AUTOSAR XML (schema 4-2-2)
package /ComponentTypes
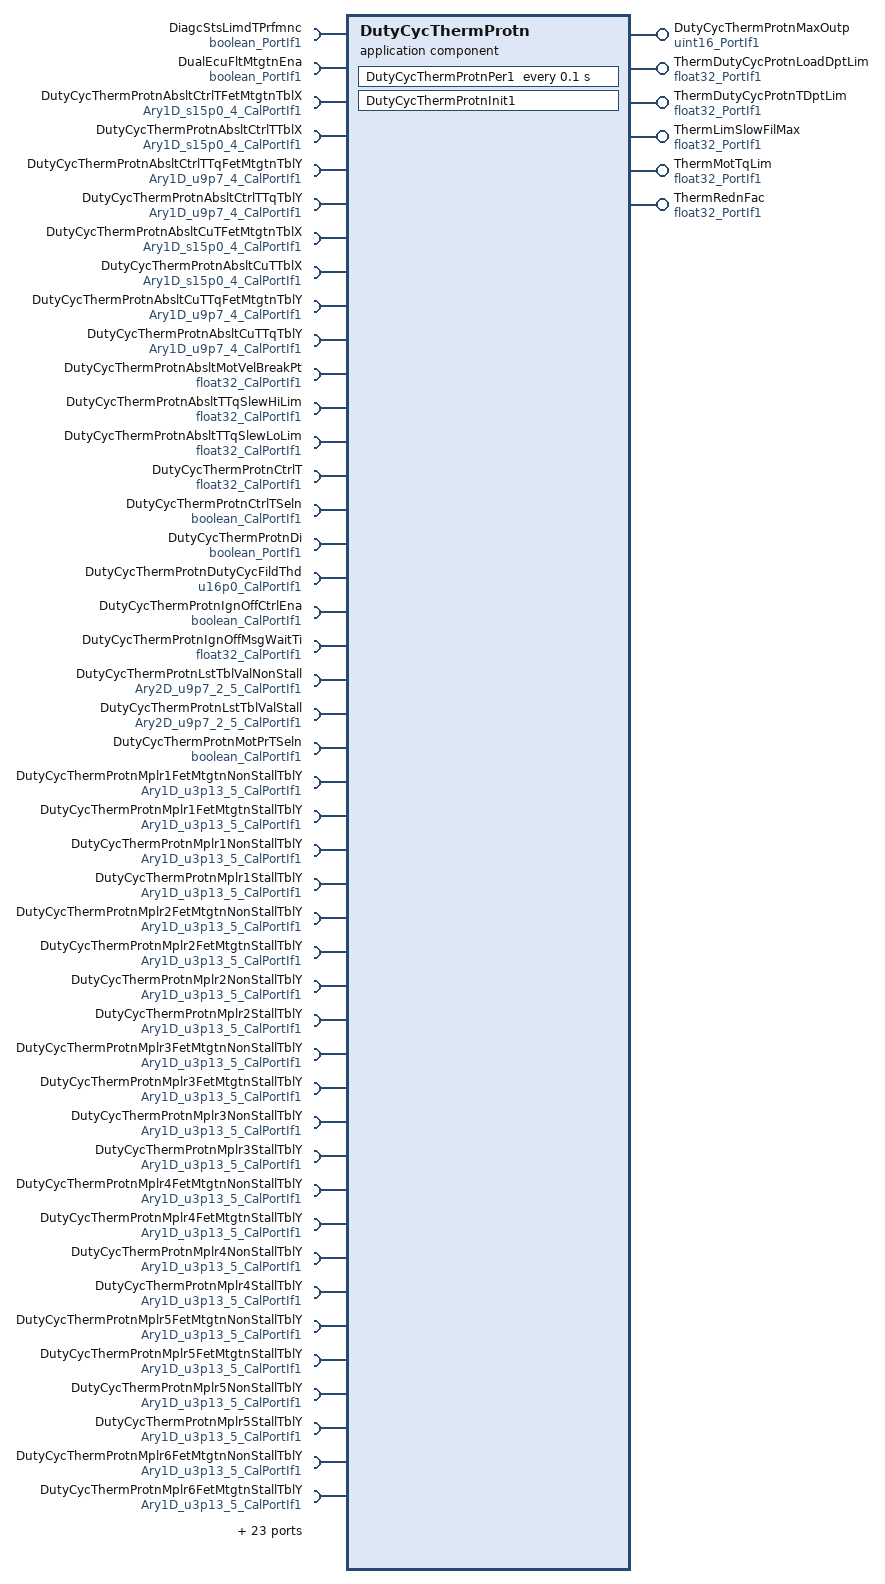
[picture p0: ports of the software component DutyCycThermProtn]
  application sw component type DutyCycThermProtn
    6 x provide port:
      DutyCycThermProtnMaxOutp: nonqueued-sender-com-spec{data-element=Val, init-value=0}, provided-interface=uint16_PortIf1
      ThermDutyCycProtnLoadDptLim: nonqueued-sender-com-spec{data-element=Val, init-value=8.8}, provided-interface=float32_PortIf1
      ThermDutyCycProtnTDptLim: nonqueued-sender-com-spec{data-element=Val, init-value=8.8}, provided-interface=float32_PortIf1
      ThermLimSlowFilMax: nonqueued-sender-com-spec{data-element=Val, init-value=0}, provided-interface=float32_PortIf1
      ThermMotTqLim: nonqueued-sender-com-spec{data-element=Val, init-value=0}, provided-interface=float32_PortIf1
      ThermRednFac: nonqueued-sender-com-spec{data-element=Val, init-value=0}, provided-interface=float32_PortIf1
    67 x require port:
      DiagcStsLimdTPrfmnc: nonqueued-receiver-com-spec{data-element=Logl, filter=data-filter-type=ALWAYS, init-value=0}, required-interface=boolean_PortIf1
      DualEcuFltMtgtnEna: nonqueued-receiver-com-spec{data-element=Logl, filter=data-filter-type=ALWAYS, init-value=0}, required-interface=boolean_PortIf1
      DutyCycThermProtnAbsltCtrlTFetMtgtnTblX: parameter-require-com-spec{init-value=[122, 123, 125, 127], parameter=Ary1D}, required-interface=Ary1D_s15p0_4_CalPortIf1
      DutyCycThermProtnAbsltCtrlTTblX: parameter-require-com-spec{init-value=[122, 123, 125, 127], parameter=Ary1D}, required-interface=Ary1D_s15p0_4_CalPortIf1
      DutyCycThermProtnAbsltCtrlTTqFetMtgtnTblY: parameter-require-com-spec{init-value=[346, 287, 234, 0], parameter=Ary1D}, required-interface=Ary1D_u9p7_4_CalPortIf1
      DutyCycThermProtnAbsltCtrlTTqTblY: parameter-require-com-spec{init-value=[346, 287, 234, 0], parameter=Ary1D}, required-interface=Ary1D_u9p7_4_CalPortIf1
      DutyCycThermProtnAbsltCuTFetMtgtnTblX: parameter-require-com-spec{init-value=[122, 123, 125, 127], parameter=Ary1D}, required-interface=Ary1D_s15p0_4_CalPortIf1
      DutyCycThermProtnAbsltCuTTblX: parameter-require-com-spec{init-value=[122, 123, 125, 127], parameter=Ary1D}, required-interface=Ary1D_s15p0_4_CalPortIf1
      DutyCycThermProtnAbsltCuTTqFetMtgtnTblY: parameter-require-com-spec{init-value=[346, 287, 234, 0], parameter=Ary1D}, required-interface=Ary1D_u9p7_4_CalPortIf1
      DutyCycThermProtnAbsltCuTTqTblY: parameter-require-com-spec{init-value=[346, 287, 234, 0], parameter=Ary1D}, required-interface=Ary1D_u9p7_4_CalPortIf1
      DutyCycThermProtnAbsltMotVelBreakPt: parameter-require-com-spec{init-value=1.375, parameter=Val}, required-interface=float32_CalPortIf1
      DutyCycThermProtnAbsltTTqSlewHiLim: parameter-require-com-spec{init-value=0.3, parameter=Val}, required-interface=float32_CalPortIf1
      DutyCycThermProtnAbsltTTqSlewLoLim: parameter-require-com-spec{init-value=0.3, parameter=Val}, required-interface=float32_CalPortIf1
      DutyCycThermProtnCtrlT: parameter-require-com-spec{init-value=70, parameter=Val}, required-interface=float32_CalPortIf1
      DutyCycThermProtnCtrlTSeln: parameter-require-com-spec{init-value=1, parameter=Logl}, required-interface=boolean_CalPortIf1
      DutyCycThermProtnDi: nonqueued-receiver-com-spec{data-element=Logl, filter=data-filter-type=ALWAYS, init-value=0}, required-interface=boolean_PortIf1
      DutyCycThermProtnDutyCycFildThd: parameter-require-com-spec{init-value=92, parameter=Val}, required-interface=u16p0_CalPortIf1
      DutyCycThermProtnIgnOffCtrlEna: parameter-require-com-spec{init-value=0, parameter=Logl}, required-interface=boolean_CalPortIf1
      DutyCycThermProtnIgnOffMsgWaitTi: parameter-require-com-spec{init-value=0.5, parameter=Val}, required-interface=float32_CalPortIf1
      DutyCycThermProtnLstTblValNonStall: parameter-require-com-spec{init-value=[[128, 128, 128, 44, 44], [128, 128, 128, 44, 44]], parameter=Ary2D}, required-interface=Ary2D_u9p7_2_5_CalPortIf1
      DutyCycThermProtnLstTblValStall: parameter-require-com-spec{init-value=[[124, 124, 124, 40, 40], [124, 124, 124, 40, 40]], parameter=Ary2D}, required-interface=Ary2D_u9p7_2_5_CalPortIf1
      DutyCycThermProtnMotPrTSeln: parameter-require-com-spec{init-value=1, parameter=Logl}, required-interface=boolean_CalPortIf1
      DutyCycThermProtnMplr1FetMtgtnNonStallTblY: parameter-require-com-spec{init-value=[127, 127, 127, 1630, 1630], parameter=Ary1D}, required-interface=Ary1D_u3p13_5_CalPortIf1
      DutyCycThermProtnMplr1FetMtgtnStallTblY: parameter-require-com-spec{init-value=[133, 133, 133, 180, 180], parameter=Ary1D}, required-interface=Ary1D_u3p13_5_CalPortIf1
      DutyCycThermProtnMplr1NonStallTblY: parameter-require-com-spec{init-value=[127, 127, 127, 1630, 1630], parameter=Ary1D}, required-interface=Ary1D_u3p13_5_CalPortIf1
      DutyCycThermProtnMplr1StallTblY: parameter-require-com-spec{init-value=[133, 133, 133, 180, 180], parameter=Ary1D}, required-interface=Ary1D_u3p13_5_CalPortIf1
      DutyCycThermProtnMplr2FetMtgtnNonStallTblY: parameter-require-com-spec{init-value=[159, 159, 159, 281, 281], parameter=Ary1D}, required-interface=Ary1D_u3p13_5_CalPortIf1
      DutyCycThermProtnMplr2FetMtgtnStallTblY: parameter-require-com-spec{init-value=[167, 167, 167, 310, 310], parameter=Ary1D}, required-interface=Ary1D_u3p13_5_CalPortIf1
      DutyCycThermProtnMplr2NonStallTblY: parameter-require-com-spec{init-value=[159, 159, 159, 281, 281], parameter=Ary1D}, required-interface=Ary1D_u3p13_5_CalPortIf1
      DutyCycThermProtnMplr2StallTblY: parameter-require-com-spec{init-value=[167, 167, 167, 310, 310], parameter=Ary1D}, required-interface=Ary1D_u3p13_5_CalPortIf1
      DutyCycThermProtnMplr3FetMtgtnNonStallTblY: parameter-require-com-spec{init-value=[199, 199, 199, 1282, 1282], parameter=Ary1D}, required-interface=Ary1D_u3p13_5_CalPortIf1
      DutyCycThermProtnMplr3FetMtgtnStallTblY: parameter-require-com-spec{init-value=[210, 210, 210, 1707, 1707], parameter=Ary1D}, required-interface=Ary1D_u3p13_5_CalPortIf1
      DutyCycThermProtnMplr3NonStallTblY: parameter-require-com-spec{init-value=[199, 199, 199, 1282, 1282], parameter=Ary1D}, required-interface=Ary1D_u3p13_5_CalPortIf1
      DutyCycThermProtnMplr3StallTblY: parameter-require-com-spec{init-value=[210, 210, 210, 1707, 1707], parameter=Ary1D}, required-interface=Ary1D_u3p13_5_CalPortIf1
      DutyCycThermProtnMplr4FetMtgtnNonStallTblY: parameter-require-com-spec{init-value=5 x 1, parameter=Ary1D}, required-interface=Ary1D_u3p13_5_CalPortIf1
      DutyCycThermProtnMplr4FetMtgtnStallTblY: parameter-require-com-spec{init-value=5 x 1, parameter=Ary1D}, required-interface=Ary1D_u3p13_5_CalPortIf1
      DutyCycThermProtnMplr4NonStallTblY: parameter-require-com-spec{init-value=5 x 1, parameter=Ary1D}, required-interface=Ary1D_u3p13_5_CalPortIf1
      DutyCycThermProtnMplr4StallTblY: parameter-require-com-spec{init-value=5 x 1, parameter=Ary1D}, required-interface=Ary1D_u3p13_5_CalPortIf1
      DutyCycThermProtnMplr5FetMtgtnNonStallTblY: parameter-require-com-spec{init-value=[998, 998, 998, 9535, 9535], parameter=Ary1D}, required-interface=Ary1D_u3p13_5_CalPortIf1
      DutyCycThermProtnMplr5FetMtgtnStallTblY: parameter-require-com-spec{init-value=[998, 998, 998, 9535, 9535], parameter=Ary1D}, required-interface=Ary1D_u3p13_5_CalPortIf1
      DutyCycThermProtnMplr5NonStallTblY: parameter-require-com-spec{init-value=[998, 998, 998, 9535, 9535], parameter=Ary1D}, required-interface=Ary1D_u3p13_5_CalPortIf1
      DutyCycThermProtnMplr5StallTblY: parameter-require-com-spec{init-value=[998, 998, 998, 9535, 9535], parameter=Ary1D}, required-interface=Ary1D_u3p13_5_CalPortIf1
      DutyCycThermProtnMplr6FetMtgtnNonStallTblY: parameter-require-com-spec{init-value=5 x 1, parameter=Ary1D}, required-interface=Ary1D_u3p13_5_CalPortIf1
      DutyCycThermProtnMplr6FetMtgtnStallTblY: parameter-require-com-spec{init-value=5 x 1, parameter=Ary1D}, required-interface=Ary1D_u3p13_5_CalPortIf1
      DutyCycThermProtnMplr6NonStallTblY: parameter-require-com-spec{init-value=5 x 1, parameter=Ary1D}, required-interface=Ary1D_u3p13_5_CalPortIf1
      DutyCycThermProtnMplr6StallTblY: parameter-require-com-spec{init-value=5 x 1, parameter=Ary1D}, required-interface=Ary1D_u3p13_5_CalPortIf1
      DutyCycThermProtnMplrFetMtgtnTblX: parameter-require-com-spec{init-value=[-40, 0, 83, 84, 85], parameter=Ary1D}, required-interface=Ary1D_s15p0_5_CalPortIf1
      DutyCycThermProtnMplrTblX: parameter-require-com-spec{init-value=[-40, 0, 83, 84, 85], parameter=Ary1D}, required-interface=Ary1D_s15p0_5_CalPortIf1
      DutyCycThermProtnMplrTSeln: parameter-require-com-spec{init-value=1, parameter=Logl}, required-interface=boolean_CalPortIf1
      DutyCycThermProtnSlowFilTSeln: parameter-require-com-spec{init-value=0, parameter=Logl}, required-interface=boolean_CalPortIf1
      DutyCycThermProtnThermLimScaFac: parameter-require-com-spec{init-value=0.5, parameter=Val}, required-interface=float32_CalPortIf1
      DutyCycThermProtnThermLoadLimTblX: parameter-require-com-spec{init-value=[[0, 76, 80, 84, 88, 92, 96, 100], [0, 76, 80, 84, 88, 92, 96, 100]], parameter=Ary2D}, required-interface=Ary2D_u16p0_2_8_CalPortIf1
      DutyCycThermProtnThermLoadLimTblY: parameter-require-com-spec{init-value=[[346, 346, 346, 346, 287, 234, 181, 128], [346, 346, 346, 346, 287, 234, 181, 128]], parameter=Ary2D}, required-interface=Ary2D_u9p7_2_8_CalPortIf1
      DutyCycThermProtnTqCmdSlewDwn: parameter-require-com-spec{init-value=0.3, parameter=Val}, required-interface=float32_CalPortIf1
      DutyCycThermProtnTqCmdSlewUp: parameter-require-com-spec{init-value=0.3, parameter=Val}, required-interface=float32_CalPortIf1
      EcuTFild: nonqueued-receiver-com-spec{data-element=Val, filter=data-filter-type=ALWAYS, init-value=25}, required-interface=float32_PortIf1
      FilStVal: required-com-specs=[EraseBlock, GetErrorStatus, InvalidateNvBlock, ReadBlock, SetRamBlockStatus, WriteBlock], required-interface=NvMService_AC3_SRBS
      IgnTiOff: nonqueued-receiver-com-spec{data-element=Val, filter=data-filter-type=ALWAYS, init-value=0}, required-interface=uint32_PortIf1
      MotAndThermProtnLoaMod: nonqueued-receiver-com-spec{data-element=Val, filter=data-filter-type=ALWAYS, init-value=0}, required-interface=uint8_PortIf1
      MotCurrPeakEstimd: nonqueued-receiver-com-spec{data-element=Val, filter=data-filter-type=ALWAYS, init-value=0}, required-interface=float32_PortIf1
      MotCurrPeakEstimdFild: nonqueued-receiver-com-spec{data-element=Val, filter=data-filter-type=ALWAYS, init-value=0}, required-interface=float32_PortIf1
      MotFetT: nonqueued-receiver-com-spec{data-element=Val, filter=data-filter-type=ALWAYS, init-value=0}, required-interface=float32_PortIf1
      MotMagT: nonqueued-receiver-com-spec{data-element=Val, filter=data-filter-type=ALWAYS, init-value=0}, required-interface=float32_PortIf1
      MotVelCrf: nonqueued-receiver-com-spec{data-element=Val, filter=data-filter-type=ALWAYS, init-value=0}, required-interface=float32_PortIf1
      MotWidgT: nonqueued-receiver-com-spec{data-element=Val, filter=data-filter-type=ALWAYS, init-value=0}, required-interface=float32_PortIf1
      SetNtcSts: client-com-spec=Oper, required-interface=SetNtcSts_PortIf1
      VehTiVld: nonqueued-receiver-com-spec{data-element=Logl, filter=data-filter-type=ALWAYS, init-value=0}, required-interface=boolean_PortIf1
    behavior DutyCycThermProtn_InternalBehavior
      ar-typed-per-instance-memorys:
        32 x data, all with sw-calibration-access=READ-ONLY:
          AbsltTLimSlewStVari: type=float32
          dDutyCycThermProtnAbsltCtrlrTTqLim: type=float32
          dDutyCycThermProtnAbsltCuTTqLim: type=float32
          dDutyCycThermProtnAbsltTTqLim: type=float32
          dDutyCycThermProtnLstTblVal: type=u9p7
          dDutyCycThermProtnLstTblValSlew: type=u9p7
          dDutyCycThermProtnMplr1: type=u3p13
          dDutyCycThermProtnMplr12T: type=float32
          dDutyCycThermProtnMplr2: type=u3p13
          dDutyCycThermProtnMplr3: type=u3p13
          dDutyCycThermProtnMplr36T: type=float32
          dDutyCycThermProtnMplr{4..6}: type=u3p13
          dDutyCycThermProtnThermLoadLim: type=float32
          dDutyCycThermProtnThermLoadLimTblYVal: type=float32
          FetLoaMtgtnEnaPrev: type=boolean
          FetMtgtnEnaCalIdx: type=uint8
          Fil1ValStVari: type=FilLpRec1
          Fil2ValStVari: type=FilLpRec1
          Fil{3..6}ValPwrUp: type=uint8
          Fild{3..6}Val: type=FilLpRec1
          FilStVal: type=DutyCycThermProtnFilStValRec1
          LstTblValRateLimrStVari: type=float32
          ReInitCntrFlg: type=boolean
          ReInitCntrVal: type=float32
      init event DutyCycThermProtn_InitEvent: start-on-event=DutyCycThermProtnInit1
      timing event TMT_DutyCycThermProtnPer1: start-on-event=DutyCycThermProtnPer1, period=0.1
      explicit-inter-runnable-variables:
        data FilStVariReInitFlg: type=boolean, init-value=0
      runnable DutyCycThermProtnInit1
        data-receive-point-by-arguments:
          4 x access:
            REC_DutyCycThermProtnDi_Logl: accessed-variable=DutyCycThermProtnDi.Logl
            REC_IgnTiOff_Val: accessed-variable=IgnTiOff.Val
            REC_MotAndThermProtnLoaMod_Val: accessed-variable=MotAndThermProtnLoaMod.Val
            REC_VehTiVld_Logl: accessed-variable=VehTiVld.Logl
        sync call SC_FilStVal_GetErrorStatus: operation=FilStVal.GetErrorStatus, timeout=0
        sync call SC_FilStVal_SetRamBlockStatus: operation=FilStVal.SetRamBlockStatus, timeout=0
        written-local-variables:
          access WRITE_FilStVariReInitFlg: accessed-variable=FilStVariReInitFlg
      runnable DutyCycThermProtnPer1
        data-receive-point-by-arguments:
          13 x access:
            REC_DiagcStsLimdTPrfmnc_Logl: accessed-variable=DiagcStsLimdTPrfmnc.Logl
            REC_DualEcuFltMtgtnEna_Logl: accessed-variable=DualEcuFltMtgtnEna.Logl
            REC_DutyCycThermProtnDi_Logl: accessed-variable=DutyCycThermProtnDi.Logl
            REC_EcuTFild_Val: accessed-variable=EcuTFild.Val
            REC_IgnTiOff_Val: accessed-variable=IgnTiOff.Val
            REC_MotAndThermProtnLoaMod_Val: accessed-variable=MotAndThermProtnLoaMod.Val
            REC_MotCurrPeakEstimd_Val: accessed-variable=MotCurrPeakEstimd.Val
            REC_MotCurrPeakEstimdFild_Val: accessed-variable=MotCurrPeakEstimdFild.Val
            REC_MotFetT_Val: accessed-variable=MotFetT.Val
            REC_MotMagT_Val: accessed-variable=MotMagT.Val
            REC_MotVelCrf_Val: accessed-variable=MotVelCrf.Val
            REC_MotWidgT_Val: accessed-variable=MotWidgT.Val
            REC_VehTiVld_Logl: accessed-variable=VehTiVld.Logl
        data-send-points:
          6 x access:
            SEND_DutyCycThermProtnMaxOutp_Val: accessed-variable=DutyCycThermProtnMaxOutp.Val
            SEND_ThermDutyCycProtnLoadDptLim_Val: accessed-variable=ThermDutyCycProtnLoadDptLim.Val
            SEND_ThermDutyCycProtnTDptLim_Val: accessed-variable=ThermDutyCycProtnTDptLim.Val
            SEND_ThermLimSlowFilMax_Val: accessed-variable=ThermLimSlowFilMax.Val
            SEND_ThermMotTqLim_Val: accessed-variable=ThermMotTqLim.Val
            SEND_ThermRednFac_Val: accessed-variable=ThermRednFac.Val
        read-local-variables:
          access READ_FilStVariReInitFlg: accessed-variable=FilStVariReInitFlg
        sync call SC_SetNtcSts_Oper: operation=SetNtcSts.Oper, timeout=0
      swc service dependency NvmFilStVal: assigned-datas=role-based-data-assignment={role=ramBlock, used-data-element=FilStVal}, assigned-ports=role-based-port-assignment={port-prototype=FilStVal, role=NvMService_AC3_SRBS}
        service-needs:
          nv block needs NvmFilStVal: n-data-sets=0, ram-block-status-control=API, readonly=false, reliability=ERROR-DETECTION, resistant-to-changed-sw=true, restore-at-start=true, store-at-shutdown=true, write-only-once=false, writing-frequency=0, writing-priority=LOW
  swc implementation DutyCycThermProtn_Implementation: behavior=DutyCycThermProtn_InternalBehavior
    code-descriptors:
      code Default: artifact-descriptors=autosar-engineering-object={short-label=Default, category=SWSRC}
